# PADCFG_CTRL_PADCFG_CTRL_CFG0_04080000h register map
Vendor: Texas Instruments
Registers are 32-bit, access per field, reset 0x8214007 unless marked. A register's access mark holds for its fields unless they carry their own. Offsets are as the file gives them; [hi:lo] are bit positions; {n}, {i} and the like mark numbered series; 'fields as' and 'values as' point back to an identical list.

## PADCFG_CTRL_CFG0 (part 2 of 2)
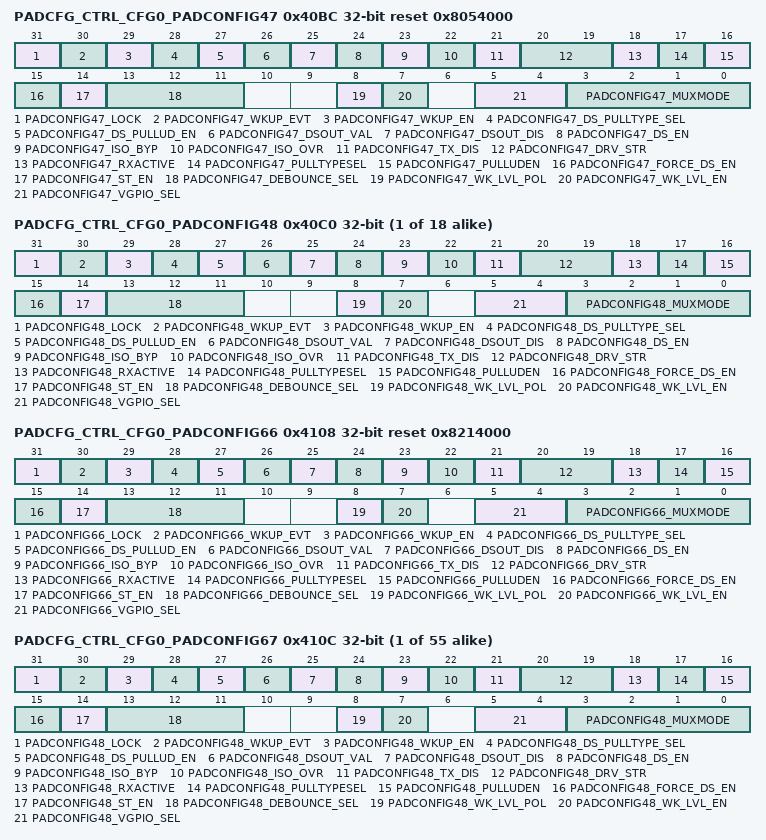
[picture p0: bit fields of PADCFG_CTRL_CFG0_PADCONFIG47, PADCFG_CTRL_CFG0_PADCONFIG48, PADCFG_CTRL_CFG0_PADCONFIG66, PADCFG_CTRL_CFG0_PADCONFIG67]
0x40BC PADCFG_CTRL_CFG0_PADCONFIG47 reset 0x8054000 — Register to control pin configuration and muxing
  [31] PADCONFIG47_LOCK rw — Lock 0 - Padconfig register is unlocked 1 - Padconfig register is locked from further writes Reset Source: mod_por_rst_n
  [30] PADCONFIG47_WKUP_EVT ro — Wakeup event status 0 - No wake event on pin 1 - Wake event occurred on pin Reset Source: mod_por_rst_n
  [29] PADCONFIG47_WKUP_EN rw — Wakeup enable 0 - Wakeup operation disabled 1 - Wakeup operation enabled Reset Source: mod_por_rst_n
  [28] PADCONFIG47_DS_PULLTYPE_SEL rw — Deep Sleep pull-up/down selection 0 - Offmode pulldown selected 1 - Offmode pullup selected Reset Source: mod_por_rst_n
  [27] PADCONFIG47_DS_PULLUD_EN rw — Deep Sleep pull-up/down enable (active low) 0 - Pullup / pulldown is enabled 1 - Pullup / pulldown is disabled Reset Source: mod_por_rst_n
  [26] PADCONFIG47_DSOUT_VAL rw — Deep Sleep output value 0 - Output value is 0 1 - Output value is 1 Reset Source: mod_por_rst_n
  [25] PADCONFIG47_DSOUT_DIS rw — Deep Sleep output disable 0 - Output enabled 1 - Output disabled Reset Source: mod_por_rst_n
  [24] PADCONFIG47_DS_EN rw — Deep Sleep override control 0 - IO keeps its previous state when Deep Sleep mode is active 1 - IO state is forced to OFF mode value when Deep Sleep mode is active Reset Source: mod_por_rst_n
  [23] PADCONFIG47_ISO_BYP rw — Isolation Bypass0 - IO isolation is preserved1 - IO isolation is bypassed Reset Source: mod_por_rst_n
  [22] PADCONFIG47_ISO_OVR rw — Isolation Override0 - IO isolation is preserved1 - IO isolation is overridden Reset Source: mod_por_rst_n
  [21] PADCONFIG47_TX_DIS rw — Driver Disable0 - Driver is enabled1 - Driver is disabled Reset Source: mod_por_rst_n
  [20:19] PADCONFIG47_DRV_STR rw — Drive Strength Control for dual volatge IOs. Selects the drive strength value for LVCMOS pins. For 1.8V only IO, bitundefined maps to Slew Control pin. Reset Source: mod_por_rst_n
  [18] PADCONFIG47_RXACTIVE rw — Input enable for the Pad0 - Receiver disabled1 - Receiver enabled Reset Source: mod_por_rst_n
  [17] PADCONFIG47_PULLTYPESEL rw — Pad Pullup / Pulldown type selection0 - Pulldown selected1 - Pullup selected Reset Source: mod_por_rst_n
  [16] PADCONFIG47_PULLUDEN rw — Pad Pullup / Pulldown enable. This is an active low signal.0 - Pullup / Pulldown enabled1 - Pullup / Pulldown disabled Reset Source: mod_por_rst_n
  [15] PADCONFIG47_FORCE_DS_EN rw — Enable pad Deep Sleep controls by overriding WKUP DM gating0 - Deep Sleep pad controls are gated by the WKUP DM1 - Activate Deep Sleep pad controls (override WKUP DM gating logic) Reset Source: mod_por_rst_n
  [14] PADCONFIG47_ST_EN rw — Receiver Schmitt Trigger enable 0 - Schmitt trigger input disabled 1 - Schmitt trigger input enabled Reset Source: mod_por_rst_n
  [13:11] PADCONFIG47_DEBOUNCE_SEL rw — Selects the debouce period for the pad. Reset Source: mod_por_rst_n
  [8] PADCONFIG47_WK_LVL_POL rw — Level Sensitive Wakeup PolarityThis bit is not relevant unless wk_lvl_en is set to 1'b1.0 - Low. A low (0) value on the pin causes a wakeup1 - High. A high (1) value on the pin causes a wakeup Reset Source: mod_por_rst_n
  [7] PADCONFIG47_WK_LVL_EN rw — Level Sensitive Wakeup Enable0 - Disabled. Wakeup is triggered by change of the pin input value1 - Enabled. Wakeup is triggered when the pin matches the value specified by wk_lvl_pol. The chosen polarity must be maintained. (e.g. until wakeup completion is confirmed) Reset Source: mod_por_rst_n
  [5:4] PADCONFIG47_VGPIO_SEL rw — Virtual MAIN_GPIO instance select.These bits select which instance of GPIO is used for this I/O pad. This allows protection between two different Processor virtual worlds. These bits have no effect if GPIO mode (muxmode=7) is not selected for the PAD. Refer Pinmux to identify if a pin supports virtual GPIO function or not.Field values (others are reserved):2'b00 - Implement GPIO in GPIO_0 instance2'b01 - Implement GPIO in GPIO_2 instance Reset Source: mod_por_rst_n
  [3:0] PADCONFIG47_MUXMODE rw — Pad functional signal mux selectionField values (others are reserved):4'b0000 - Mux Mode 04'b0001 - Mux Mode 14'b0010 - Mux Mode 24'b0011 - Mux Mode 34'b0100 - Mux Mode 44'b0101 - Mux Mode 54'b0110 - Mux Mode 64'b0111 - Mux Mode 74'b1000 - Mux Mode 84'b1001 - Mux Mode 94'b1010 - Mux Mode 104'b1011 - Mux Mode 114'b1100 - Mux Mode 124'b1101 - Mux Mode 134'b1110 - Mux Mode 144'b1111 - Mux Mode 15 Reset Source: mod_por_rst_n
{0x4000+4i} PADCFG_CTRL_CFG0_PADCONFIG{i} (i=48..65) — Register to control pin configuration and muxing
  [31] PADCONFIG{i}_LOCK rw — Lock 0 - Padconfig register is unlocked 1 - Padconfig register is locked from further writes Reset Source: mod_por_rst_n
  [30] PADCONFIG{i}_WKUP_EVT ro — Wakeup event status 0 - No wake event on pin 1 - Wake event occurred on pin Reset Source: mod_por_rst_n
  [29] PADCONFIG{i}_WKUP_EN rw — Wakeup enable 0 - Wakeup operation disabled 1 - Wakeup operation enabled Reset Source: mod_por_rst_n
  [28] PADCONFIG{i}_DS_PULLTYPE_SEL rw — Deep Sleep pull-up/down selection 0 - Offmode pulldown selected 1 - Offmode pullup selected Reset Source: mod_por_rst_n
  [27] PADCONFIG{i}_DS_PULLUD_EN rw — Deep Sleep pull-up/down enable (active low) 0 - Pullup / pulldown is enabled 1 - Pullup / pulldown is disabled Reset Source: mod_por_rst_n
  [26] PADCONFIG{i}_DSOUT_VAL rw — Deep Sleep output value 0 - Output value is 0 1 - Output value is 1 Reset Source: mod_por_rst_n
  [25] PADCONFIG{i}_DSOUT_DIS rw — Deep Sleep output disable 0 - Output enabled 1 - Output disabled Reset Source: mod_por_rst_n
  [24] PADCONFIG{i}_DS_EN rw — Deep Sleep override control 0 - IO keeps its previous state when Deep Sleep mode is active 1 - IO state is forced to OFF mode value when Deep Sleep mode is active Reset Source: mod_por_rst_n
  [23] PADCONFIG{i}_ISO_BYP rw — Isolation Bypass0 - IO isolation is preserved1 - IO isolation is bypassed Reset Source: mod_por_rst_n
  [22] PADCONFIG{i}_ISO_OVR rw — Isolation Override0 - IO isolation is preserved1 - IO isolation is overridden Reset Source: mod_por_rst_n
  [21] PADCONFIG{i}_TX_DIS rw — Driver Disable0 - Driver is enabled1 - Driver is disabled Reset Source: mod_por_rst_n
  [20:19] PADCONFIG{i}_DRV_STR rw — Drive Strength Control for dual volatge IOs. Selects the drive strength value for LVCMOS pins. For 1.8V only IO, bitundefined maps to Slew Control pin. Reset Source: mod_por_rst_n
  [18] PADCONFIG{i}_RXACTIVE rw — Input enable for the Pad0 - Receiver disabled1 - Receiver enabled Reset Source: mod_por_rst_n
  [17] PADCONFIG{i}_PULLTYPESEL rw — Pad Pullup / Pulldown type selection0 - Pulldown selected1 - Pullup selected Reset Source: mod_por_rst_n
  [16] PADCONFIG{i}_PULLUDEN rw — Pad Pullup / Pulldown enable. This is an active low signal.0 - Pullup / Pulldown enabled1 - Pullup / Pulldown disabled Reset Source: mod_por_rst_n
  [15] PADCONFIG{i}_FORCE_DS_EN rw — Enable pad Deep Sleep controls by overriding WKUP DM gating0 - Deep Sleep pad controls are gated by the WKUP DM1 - Activate Deep Sleep pad controls (override WKUP DM gating logic) Reset Source: mod_por_rst_n
  [14] PADCONFIG{i}_ST_EN rw — Receiver Schmitt Trigger enable 0 - Schmitt trigger input disabled 1 - Schmitt trigger input enabled Reset Source: mod_por_rst_n
  [13:11] PADCONFIG{i}_DEBOUNCE_SEL rw — Selects the debouce period for the pad. Reset Source: mod_por_rst_n
  [8] PADCONFIG{i}_WK_LVL_POL rw — Level Sensitive Wakeup PolarityThis bit is not relevant unless wk_lvl_en is set to 1'b1.0 - Low. A low (0) value on the pin causes a wakeup1 - High. A high (1) value on the pin causes a wakeup Reset Source: mod_por_rst_n
  [7] PADCONFIG{i}_WK_LVL_EN rw — Level Sensitive Wakeup Enable0 - Disabled. Wakeup is triggered by change of the pin input value1 - Enabled. Wakeup is triggered when the pin matches the value specified by wk_lvl_pol. The chosen polarity must be maintained. (e.g. until wakeup completion is confirmed) Reset Source: mod_por_rst_n
  [5:4] PADCONFIG{i}_VGPIO_SEL rw — Virtual MAIN_GPIO instance select.These bits select which instance of GPIO is used for this I/O pad. This allows protection between two different Processor virtual worlds. These bits have no effect if GPIO mode (muxmode=7) is not selected for the PAD. Refer Pinmux to identify if a pin supports virtual GPIO function or not.Field values (others are reserved):2'b00 - Implement GPIO in GPIO_0 instance2'b01 - Implement GPIO in GPIO_2 instance Reset Source: mod_por_rst_n
  [3:0] PADCONFIG{i}_MUXMODE rw — Pad functional signal mux selectionField values (others are reserved):4'b0000 - Mux Mode 04'b0001 - Mux Mode 14'b0010 - Mux Mode 24'b0011 - Mux Mode 34'b0100 - Mux Mode 44'b0101 - Mux Mode 54'b0110 - Mux Mode 64'b0111 - Mux Mode 74'b1000 - Mux Mode 84'b1001 - Mux Mode 94'b1010 - Mux Mode 104'b1011 - Mux Mode 114'b1100 - Mux Mode 124'b1101 - Mux Mode 134'b1110 - Mux Mode 144'b1111 - Mux Mode 15 Reset Source: mod_por_rst_n
0x4108 PADCFG_CTRL_CFG0_PADCONFIG66 reset 0x8214000 — Register to control pin configuration and muxing
  [31] PADCONFIG66_LOCK rw — Lock 0 - Padconfig register is unlocked 1 - Padconfig register is locked from further writes Reset Source: mod_por_rst_n
  [30] PADCONFIG66_WKUP_EVT ro — Wakeup event status 0 - No wake event on pin 1 - Wake event occurred on pin Reset Source: mod_por_rst_n
  [29] PADCONFIG66_WKUP_EN rw — Wakeup enable 0 - Wakeup operation disabled 1 - Wakeup operation enabled Reset Source: mod_por_rst_n
  [28] PADCONFIG66_DS_PULLTYPE_SEL rw — Deep Sleep pull-up/down selection 0 - Offmode pulldown selected 1 - Offmode pullup selected Reset Source: mod_por_rst_n
  [27] PADCONFIG66_DS_PULLUD_EN rw — Deep Sleep pull-up/down enable (active low) 0 - Pullup / pulldown is enabled 1 - Pullup / pulldown is disabled Reset Source: mod_por_rst_n
  [26] PADCONFIG66_DSOUT_VAL rw — Deep Sleep output value 0 - Output value is 0 1 - Output value is 1 Reset Source: mod_por_rst_n
  [25] PADCONFIG66_DSOUT_DIS rw — Deep Sleep output disable 0 - Output enabled 1 - Output disabled Reset Source: mod_por_rst_n
  [24] PADCONFIG66_DS_EN rw — Deep Sleep override control 0 - IO keeps its previous state when Deep Sleep mode is active 1 - IO state is forced to OFF mode value when Deep Sleep mode is active Reset Source: mod_por_rst_n
  [23] PADCONFIG66_ISO_BYP rw — Isolation Bypass0 - IO isolation is preserved1 - IO isolation is bypassed Reset Source: mod_por_rst_n
  [22] PADCONFIG66_ISO_OVR rw — Isolation Override0 - IO isolation is preserved1 - IO isolation is overridden Reset Source: mod_por_rst_n
  [21] PADCONFIG66_TX_DIS rw — Driver Disable0 - Driver is enabled1 - Driver is disabled Reset Source: mod_por_rst_n
  [20:19] PADCONFIG66_DRV_STR rw — Drive Strength Control for dual volatge IOs. Selects the drive strength value for LVCMOS pins. For 1.8V only IO, bitundefined maps to Slew Control pin. Reset Source: mod_por_rst_n
  [18] PADCONFIG66_RXACTIVE rw — Input enable for the Pad0 - Receiver disabled1 - Receiver enabled Reset Source: mod_por_rst_n
  [17] PADCONFIG66_PULLTYPESEL rw — Pad Pullup / Pulldown type selection0 - Pulldown selected1 - Pullup selected Reset Source: mod_por_rst_n
  [16] PADCONFIG66_PULLUDEN rw — Pad Pullup / Pulldown enable. This is an active low signal.0 - Pullup / Pulldown enabled1 - Pullup / Pulldown disabled Reset Source: mod_por_rst_n
  [15] PADCONFIG66_FORCE_DS_EN rw — Enable pad Deep Sleep controls by overriding WKUP DM gating0 - Deep Sleep pad controls are gated by the WKUP DM1 - Activate Deep Sleep pad controls (override WKUP DM gating logic) Reset Source: mod_por_rst_n
  [14] PADCONFIG66_ST_EN rw — Receiver Schmitt Trigger enable 0 - Schmitt trigger input disabled 1 - Schmitt trigger input enabled Reset Source: mod_por_rst_n
  [13:11] PADCONFIG66_DEBOUNCE_SEL rw — Selects the debouce period for the pad. Reset Source: mod_por_rst_n
  [8] PADCONFIG66_WK_LVL_POL rw — Level Sensitive Wakeup PolarityThis bit is not relevant unless wk_lvl_en is set to 1'b1.0 - Low. A low (0) value on the pin causes a wakeup1 - High. A high (1) value on the pin causes a wakeup Reset Source: mod_por_rst_n
  [7] PADCONFIG66_WK_LVL_EN rw — Level Sensitive Wakeup Enable0 - Disabled. Wakeup is triggered by change of the pin input value1 - Enabled. Wakeup is triggered when the pin matches the value specified by wk_lvl_pol. The chosen polarity must be maintained. (e.g. until wakeup completion is confirmed) Reset Source: mod_por_rst_n
  [5:4] PADCONFIG66_VGPIO_SEL rw — Virtual MAIN_GPIO instance select.These bits select which instance of GPIO is used for this I/O pad. This allows protection between two different Processor virtual worlds. These bits have no effect if GPIO mode (muxmode=7) is not selected for the PAD. Refer Pinmux to identify if a pin supports virtual GPIO function or not.Field values (others are reserved):2'b00 - Implement GPIO in GPIO_0 instance2'b01 - Implement GPIO in GPIO_2 instance Reset Source: mod_por_rst_n
  [3:0] PADCONFIG66_MUXMODE rw — Pad functional signal mux selectionField values (others are reserved):4'b0000 - Mux Mode 04'b0001 - Mux Mode 14'b0010 - Mux Mode 24'b0011 - Mux Mode 34'b0100 - Mux Mode 44'b0101 - Mux Mode 54'b0110 - Mux Mode 64'b0111 - Mux Mode 74'b1000 - Mux Mode 84'b1001 - Mux Mode 94'b1010 - Mux Mode 104'b1011 - Mux Mode 114'b1100 - Mux Mode 124'b1101 - Mux Mode 134'b1110 - Mux Mode 144'b1111 - Mux Mode 15 Reset Source: mod_por_rst_n
{0x4000+4i} PADCFG_CTRL_CFG0_PADCONFIG{i} (i=67..121) — Register to control pin configuration and muxing
  fields as PADCFG_CTRL_CFG0_PADCONFIG48
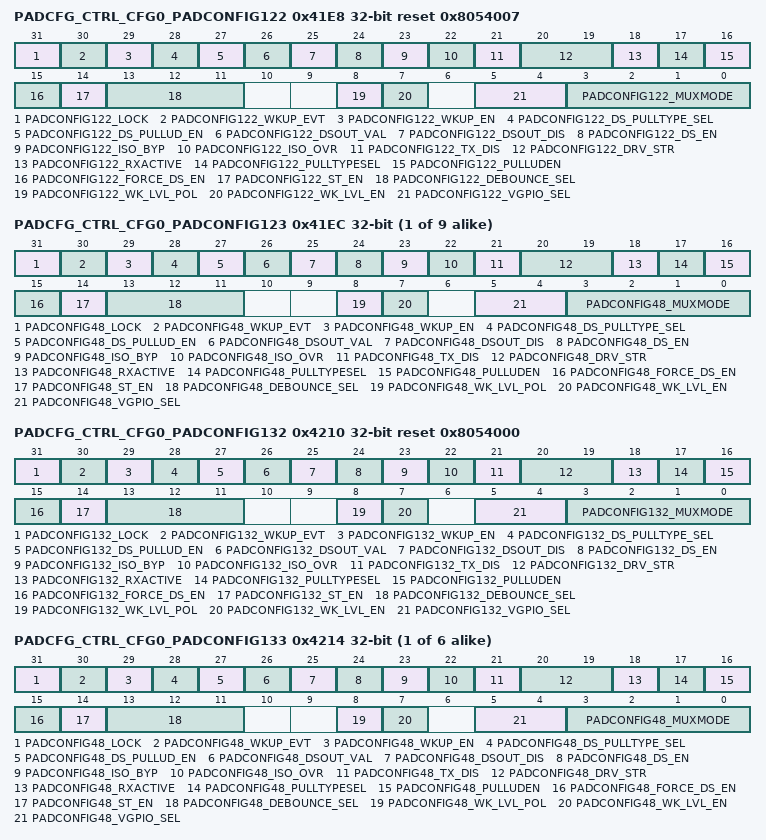
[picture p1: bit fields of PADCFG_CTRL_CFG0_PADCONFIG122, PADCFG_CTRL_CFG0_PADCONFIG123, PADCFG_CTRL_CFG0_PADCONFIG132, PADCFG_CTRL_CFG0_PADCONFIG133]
0x41E8 PADCFG_CTRL_CFG0_PADCONFIG122 reset 0x8054007 — Register to control pin configuration and muxing
  [31] PADCONFIG122_LOCK rw — Lock 0 - Padconfig register is unlocked 1 - Padconfig register is locked from further writes Reset Source: mod_por_rst_n
  [30] PADCONFIG122_WKUP_EVT ro — Wakeup event status 0 - No wake event on pin 1 - Wake event occurred on pin Reset Source: mod_por_rst_n
  [29] PADCONFIG122_WKUP_EN rw — Wakeup enable 0 - Wakeup operation disabled 1 - Wakeup operation enabled Reset Source: mod_por_rst_n
  [28] PADCONFIG122_DS_PULLTYPE_SEL rw — Deep Sleep pull-up/down selection 0 - Offmode pulldown selected 1 - Offmode pullup selected Reset Source: mod_por_rst_n
  [27] PADCONFIG122_DS_PULLUD_EN rw — Deep Sleep pull-up/down enable (active low) 0 - Pullup / pulldown is enabled 1 - Pullup / pulldown is disabled Reset Source: mod_por_rst_n
  [26] PADCONFIG122_DSOUT_VAL rw — Deep Sleep output value 0 - Output value is 0 1 - Output value is 1 Reset Source: mod_por_rst_n
  [25] PADCONFIG122_DSOUT_DIS rw — Deep Sleep output disable 0 - Output enabled 1 - Output disabled Reset Source: mod_por_rst_n
  [24] PADCONFIG122_DS_EN rw — Deep Sleep override control 0 - IO keeps its previous state when Deep Sleep mode is active 1 - IO state is forced to OFF mode value when Deep Sleep mode is active Reset Source: mod_por_rst_n
  [23] PADCONFIG122_ISO_BYP rw — Isolation Bypass0 - IO isolation is preserved1 - IO isolation is bypassed Reset Source: mod_por_rst_n
  [22] PADCONFIG122_ISO_OVR rw — Isolation Override0 - IO isolation is preserved1 - IO isolation is overridden Reset Source: mod_por_rst_n
  [21] PADCONFIG122_TX_DIS rw — Driver Disable0 - Driver is enabled1 - Driver is disabled Reset Source: mod_por_rst_n
  [20:19] PADCONFIG122_DRV_STR rw — Drive Strength Control for dual volatge IOs. Selects the drive strength value for LVCMOS pins. For 1.8V only IO, bitundefined maps to Slew Control pin. Reset Source: mod_por_rst_n
  [18] PADCONFIG122_RXACTIVE rw — Input enable for the Pad0 - Receiver disabled1 - Receiver enabled Reset Source: mod_por_rst_n
  [17] PADCONFIG122_PULLTYPESEL rw — Pad Pullup / Pulldown type selection0 - Pulldown selected1 - Pullup selected Reset Source: mod_por_rst_n
  [16] PADCONFIG122_PULLUDEN rw — Pad Pullup / Pulldown enable. This is an active low signal.0 - Pullup / Pulldown enabled1 - Pullup / Pulldown disabled Reset Source: mod_por_rst_n
  [15] PADCONFIG122_FORCE_DS_EN rw — Enable pad Deep Sleep controls by overriding WKUP DM gating0 - Deep Sleep pad controls are gated by the WKUP DM1 - Activate Deep Sleep pad controls (override WKUP DM gating logic) Reset Source: mod_por_rst_n
  [14] PADCONFIG122_ST_EN rw — Receiver Schmitt Trigger enable 0 - Schmitt trigger input disabled 1 - Schmitt trigger input enabled Reset Source: mod_por_rst_n
  [13:11] PADCONFIG122_DEBOUNCE_SEL rw — Selects the debouce period for the pad. Reset Source: mod_por_rst_n
  [8] PADCONFIG122_WK_LVL_POL rw — Level Sensitive Wakeup PolarityThis bit is not relevant unless wk_lvl_en is set to 1'b1.0 - Low. A low (0) value on the pin causes a wakeup1 - High. A high (1) value on the pin causes a wakeup Reset Source: mod_por_rst_n
  [7] PADCONFIG122_WK_LVL_EN rw — Level Sensitive Wakeup Enable0 - Disabled. Wakeup is triggered by change of the pin input value1 - Enabled. Wakeup is triggered when the pin matches the value specified by wk_lvl_pol. The chosen polarity must be maintained. (e.g. until wakeup completion is confirmed) Reset Source: mod_por_rst_n
  [5:4] PADCONFIG122_VGPIO_SEL rw — Virtual MAIN_GPIO instance select.These bits select which instance of GPIO is used for this I/O pad. This allows protection between two different Processor virtual worlds. These bits have no effect if GPIO mode (muxmode=7) is not selected for the PAD. Refer Pinmux to identify if a pin supports virtual GPIO function or not.Field values (others are reserved):2'b00 - Implement GPIO in GPIO_0 instance2'b01 - Implement GPIO in GPIO_2 instance Reset Source: mod_por_rst_n
  [3:0] PADCONFIG122_MUXMODE rw — Pad functional signal mux selectionField values (others are reserved):4'b0000 - Mux Mode 04'b0001 - Mux Mode 14'b0010 - Mux Mode 24'b0011 - Mux Mode 34'b0100 - Mux Mode 44'b0101 - Mux Mode 54'b0110 - Mux Mode 64'b0111 - Mux Mode 74'b1000 - Mux Mode 84'b1001 - Mux Mode 94'b1010 - Mux Mode 104'b1011 - Mux Mode 114'b1100 - Mux Mode 124'b1101 - Mux Mode 134'b1110 - Mux Mode 144'b1111 - Mux Mode 15 Reset Source: mod_por_rst_n
{0x4000+4i} PADCFG_CTRL_CFG0_PADCONFIG{i} (i=123..131) — Register to control pin configuration and muxing
  fields as PADCFG_CTRL_CFG0_PADCONFIG48
0x4210 PADCFG_CTRL_CFG0_PADCONFIG132 reset 0x8054000 — Register to control pin configuration and muxing
  [31] PADCONFIG132_LOCK rw — Lock 0 - Padconfig register is unlocked 1 - Padconfig register is locked from further writes Reset Source: mod_por_rst_n
  [30] PADCONFIG132_WKUP_EVT ro — Wakeup event status 0 - No wake event on pin 1 - Wake event occurred on pin Reset Source: mod_por_rst_n
  [29] PADCONFIG132_WKUP_EN rw — Wakeup enable 0 - Wakeup operation disabled 1 - Wakeup operation enabled Reset Source: mod_por_rst_n
  [28] PADCONFIG132_DS_PULLTYPE_SEL rw — Deep Sleep pull-up/down selection 0 - Offmode pulldown selected 1 - Offmode pullup selected Reset Source: mod_por_rst_n
  [27] PADCONFIG132_DS_PULLUD_EN rw — Deep Sleep pull-up/down enable (active low) 0 - Pullup / pulldown is enabled 1 - Pullup / pulldown is disabled Reset Source: mod_por_rst_n
  [26] PADCONFIG132_DSOUT_VAL rw — Deep Sleep output value 0 - Output value is 0 1 - Output value is 1 Reset Source: mod_por_rst_n
  [25] PADCONFIG132_DSOUT_DIS rw — Deep Sleep output disable 0 - Output enabled 1 - Output disabled Reset Source: mod_por_rst_n
  [24] PADCONFIG132_DS_EN rw — Deep Sleep override control 0 - IO keeps its previous state when Deep Sleep mode is active 1 - IO state is forced to OFF mode value when Deep Sleep mode is active Reset Source: mod_por_rst_n
  [23] PADCONFIG132_ISO_BYP rw — Isolation Bypass0 - IO isolation is preserved1 - IO isolation is bypassed Reset Source: mod_por_rst_n
  [22] PADCONFIG132_ISO_OVR rw — Isolation Override0 - IO isolation is preserved1 - IO isolation is overridden Reset Source: mod_por_rst_n
  [21] PADCONFIG132_TX_DIS rw — Driver Disable0 - Driver is enabled1 - Driver is disabled Reset Source: mod_por_rst_n
  [20:19] PADCONFIG132_DRV_STR rw — Drive Strength Control for dual volatge IOs. Selects the drive strength value for LVCMOS pins. For 1.8V only IO, bitundefined maps to Slew Control pin. Reset Source: mod_por_rst_n
  [18] PADCONFIG132_RXACTIVE rw — Input enable for the Pad0 - Receiver disabled1 - Receiver enabled Reset Source: mod_por_rst_n
  [17] PADCONFIG132_PULLTYPESEL rw — Pad Pullup / Pulldown type selection0 - Pulldown selected1 - Pullup selected Reset Source: mod_por_rst_n
  [16] PADCONFIG132_PULLUDEN rw — Pad Pullup / Pulldown enable. This is an active low signal.0 - Pullup / Pulldown enabled1 - Pullup / Pulldown disabled Reset Source: mod_por_rst_n
  [15] PADCONFIG132_FORCE_DS_EN rw — Enable pad Deep Sleep controls by overriding WKUP DM gating0 - Deep Sleep pad controls are gated by the WKUP DM1 - Activate Deep Sleep pad controls (override WKUP DM gating logic) Reset Source: mod_por_rst_n
  [14] PADCONFIG132_ST_EN rw — Receiver Schmitt Trigger enable 0 - Schmitt trigger input disabled 1 - Schmitt trigger input enabled Reset Source: mod_por_rst_n
  [13:11] PADCONFIG132_DEBOUNCE_SEL rw — Selects the debouce period for the pad. Reset Source: mod_por_rst_n
  [8] PADCONFIG132_WK_LVL_POL rw — Level Sensitive Wakeup PolarityThis bit is not relevant unless wk_lvl_en is set to 1'b1.0 - Low. A low (0) value on the pin causes a wakeup1 - High. A high (1) value on the pin causes a wakeup Reset Source: mod_por_rst_n
  [7] PADCONFIG132_WK_LVL_EN rw — Level Sensitive Wakeup Enable0 - Disabled. Wakeup is triggered by change of the pin input value1 - Enabled. Wakeup is triggered when the pin matches the value specified by wk_lvl_pol. The chosen polarity must be maintained. (e.g. until wakeup completion is confirmed) Reset Source: mod_por_rst_n
  [5:4] PADCONFIG132_VGPIO_SEL rw — Virtual MAIN_GPIO instance select.These bits select which instance of GPIO is used for this I/O pad. This allows protection between two different Processor virtual worlds. These bits have no effect if GPIO mode (muxmode=7) is not selected for the PAD. Refer Pinmux to identify if a pin supports virtual GPIO function or not.Field values (others are reserved):2'b00 - Implement GPIO in GPIO_0 instance2'b01 - Implement GPIO in GPIO_2 instance Reset Source: mod_por_rst_n
  [3:0] PADCONFIG132_MUXMODE rw — Pad functional signal mux selectionField values (others are reserved):4'b0000 - Mux Mode 04'b0001 - Mux Mode 14'b0010 - Mux Mode 24'b0011 - Mux Mode 34'b0100 - Mux Mode 44'b0101 - Mux Mode 54'b0110 - Mux Mode 64'b0111 - Mux Mode 74'b1000 - Mux Mode 84'b1001 - Mux Mode 94'b1010 - Mux Mode 104'b1011 - Mux Mode 114'b1100 - Mux Mode 124'b1101 - Mux Mode 134'b1110 - Mux Mode 144'b1111 - Mux Mode 15 Reset Source: mod_por_rst_n
{0x4000+4i} PADCFG_CTRL_CFG0_PADCONFIG{i} (i=133..138) — Register to control pin configuration and muxing
  fields as PADCFG_CTRL_CFG0_PADCONFIG48
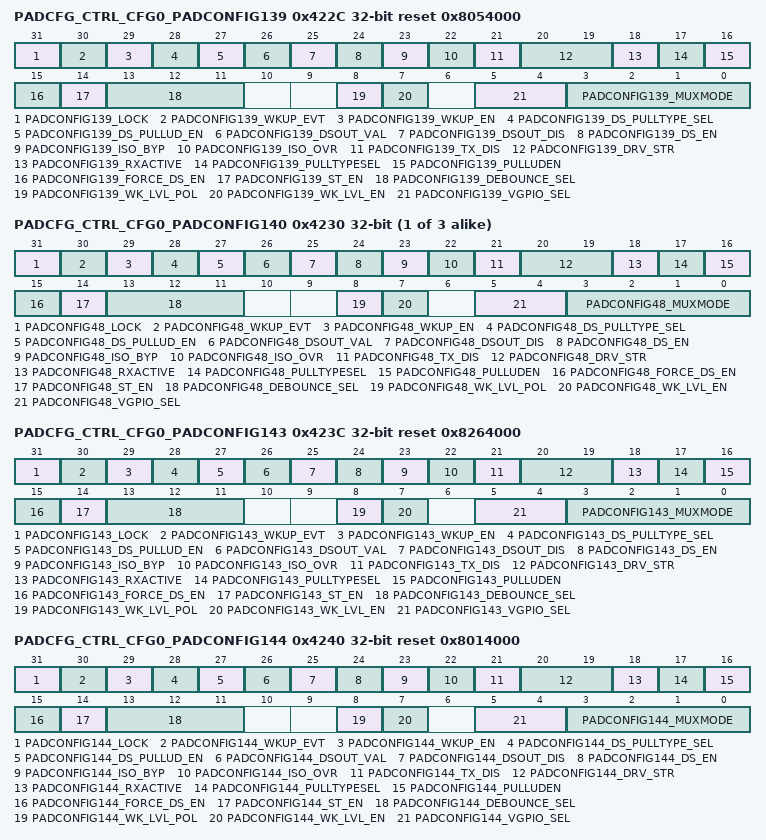
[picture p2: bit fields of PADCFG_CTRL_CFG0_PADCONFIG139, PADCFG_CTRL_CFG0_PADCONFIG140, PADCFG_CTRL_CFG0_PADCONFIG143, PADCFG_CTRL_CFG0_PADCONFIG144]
0x422C PADCFG_CTRL_CFG0_PADCONFIG139 reset 0x8054000 — Register to control pin configuration and muxing
  [31] PADCONFIG139_LOCK rw — Lock 0 - Padconfig register is unlocked 1 - Padconfig register is locked from further writes Reset Source: mod_por_rst_n
  [30] PADCONFIG139_WKUP_EVT ro — Wakeup event status 0 - No wake event on pin 1 - Wake event occurred on pin Reset Source: mod_por_rst_n
  [29] PADCONFIG139_WKUP_EN rw — Wakeup enable 0 - Wakeup operation disabled 1 - Wakeup operation enabled Reset Source: mod_por_rst_n
  [28] PADCONFIG139_DS_PULLTYPE_SEL rw — Deep Sleep pull-up/down selection 0 - Offmode pulldown selected 1 - Offmode pullup selected Reset Source: mod_por_rst_n
  [27] PADCONFIG139_DS_PULLUD_EN rw — Deep Sleep pull-up/down enable (active low) 0 - Pullup / pulldown is enabled 1 - Pullup / pulldown is disabled Reset Source: mod_por_rst_n
  [26] PADCONFIG139_DSOUT_VAL rw — Deep Sleep output value 0 - Output value is 0 1 - Output value is 1 Reset Source: mod_por_rst_n
  [25] PADCONFIG139_DSOUT_DIS rw — Deep Sleep output disable 0 - Output enabled 1 - Output disabled Reset Source: mod_por_rst_n
  [24] PADCONFIG139_DS_EN rw — Deep Sleep override control 0 - IO keeps its previous state when Deep Sleep mode is active 1 - IO state is forced to OFF mode value when Deep Sleep mode is active Reset Source: mod_por_rst_n
  [23] PADCONFIG139_ISO_BYP rw — Isolation Bypass0 - IO isolation is preserved1 - IO isolation is bypassed Reset Source: mod_por_rst_n
  [22] PADCONFIG139_ISO_OVR rw — Isolation Override0 - IO isolation is preserved1 - IO isolation is overridden Reset Source: mod_por_rst_n
  [21] PADCONFIG139_TX_DIS rw — Driver Disable0 - Driver is enabled1 - Driver is disabled Reset Source: mod_por_rst_n
  [20:19] PADCONFIG139_DRV_STR rw — Drive Strength Control for dual volatge IOs. Selects the drive strength value for LVCMOS pins. For 1.8V only IO, bitundefined maps to Slew Control pin. Reset Source: mod_por_rst_n
  [18] PADCONFIG139_RXACTIVE rw — Input enable for the Pad0 - Receiver disabled1 - Receiver enabled Reset Source: mod_por_rst_n
  [17] PADCONFIG139_PULLTYPESEL rw — Pad Pullup / Pulldown type selection0 - Pulldown selected1 - Pullup selected Reset Source: mod_por_rst_n
  [16] PADCONFIG139_PULLUDEN rw — Pad Pullup / Pulldown enable. This is an active low signal.0 - Pullup / Pulldown enabled1 - Pullup / Pulldown disabled Reset Source: mod_por_rst_n
  [15] PADCONFIG139_FORCE_DS_EN rw — Enable pad Deep Sleep controls by overriding WKUP DM gating0 - Deep Sleep pad controls are gated by the WKUP DM1 - Activate Deep Sleep pad controls (override WKUP DM gating logic) Reset Source: mod_por_rst_n
  [14] PADCONFIG139_ST_EN rw — Receiver Schmitt Trigger enable 0 - Schmitt trigger input disabled 1 - Schmitt trigger input enabled Reset Source: mod_por_rst_n
  [13:11] PADCONFIG139_DEBOUNCE_SEL rw — Selects the debouce period for the pad. Reset Source: mod_por_rst_n
  [8] PADCONFIG139_WK_LVL_POL rw — Level Sensitive Wakeup PolarityThis bit is not relevant unless wk_lvl_en is set to 1'b1.0 - Low. A low (0) value on the pin causes a wakeup1 - High. A high (1) value on the pin causes a wakeup Reset Source: mod_por_rst_n
  [7] PADCONFIG139_WK_LVL_EN rw — Level Sensitive Wakeup Enable0 - Disabled. Wakeup is triggered by change of the pin input value1 - Enabled. Wakeup is triggered when the pin matches the value specified by wk_lvl_pol. The chosen polarity must be maintained. (e.g. until wakeup completion is confirmed) Reset Source: mod_por_rst_n
  [5:4] PADCONFIG139_VGPIO_SEL rw — Virtual MAIN_GPIO instance select.These bits select which instance of GPIO is used for this I/O pad. This allows protection between two different Processor virtual worlds. These bits have no effect if GPIO mode (muxmode=7) is not selected for the PAD. Refer Pinmux to identify if a pin supports virtual GPIO function or not.Field values (others are reserved):2'b00 - Implement GPIO in GPIO_0 instance2'b01 - Implement GPIO in GPIO_2 instance Reset Source: mod_por_rst_n
  [3:0] PADCONFIG139_MUXMODE rw — Pad functional signal mux selectionField values (others are reserved):4'b0000 - Mux Mode 04'b0001 - Mux Mode 14'b0010 - Mux Mode 24'b0011 - Mux Mode 34'b0100 - Mux Mode 44'b0101 - Mux Mode 54'b0110 - Mux Mode 64'b0111 - Mux Mode 74'b1000 - Mux Mode 84'b1001 - Mux Mode 94'b1010 - Mux Mode 104'b1011 - Mux Mode 114'b1100 - Mux Mode 124'b1101 - Mux Mode 134'b1110 - Mux Mode 144'b1111 - Mux Mode 15 Reset Source: mod_por_rst_n
{0x4000+4i} PADCFG_CTRL_CFG0_PADCONFIG{i} (i=140..142) — Register to control pin configuration and muxing
  fields as PADCFG_CTRL_CFG0_PADCONFIG48
0x423C PADCFG_CTRL_CFG0_PADCONFIG143 reset 0x8264000 — Register to control pin configuration and muxing
  [31] PADCONFIG143_LOCK rw — Lock 0 - Padconfig register is unlocked 1 - Padconfig register is locked from further writes Reset Source: mod_por_rst_n
  [30] PADCONFIG143_WKUP_EVT ro — Wakeup event status 0 - No wake event on pin 1 - Wake event occurred on pin Reset Source: mod_por_rst_n
  [29] PADCONFIG143_WKUP_EN rw — Wakeup enable 0 - Wakeup operation disabled 1 - Wakeup operation enabled Reset Source: mod_por_rst_n
  [28] PADCONFIG143_DS_PULLTYPE_SEL rw — Deep Sleep pull-up/down selection 0 - Offmode pulldown selected 1 - Offmode pullup selected Reset Source: mod_por_rst_n
  [27] PADCONFIG143_DS_PULLUD_EN rw — Deep Sleep pull-up/down enable (active low) 0 - Pullup / pulldown is enabled 1 - Pullup / pulldown is disabled Reset Source: mod_por_rst_n
  [26] PADCONFIG143_DSOUT_VAL rw — Deep Sleep output value 0 - Output value is 0 1 - Output value is 1 Reset Source: mod_por_rst_n
  [25] PADCONFIG143_DSOUT_DIS rw — Deep Sleep output disable 0 - Output enabled 1 - Output disabled Reset Source: mod_por_rst_n
  [24] PADCONFIG143_DS_EN rw — Deep Sleep override control 0 - IO keeps its previous state when Deep Sleep mode is active 1 - IO state is forced to OFF mode value when Deep Sleep mode is active Reset Source: mod_por_rst_n
  [23] PADCONFIG143_ISO_BYP rw — Isolation Bypass0 - IO isolation is preserved1 - IO isolation is bypassed Reset Source: mod_por_rst_n
  [22] PADCONFIG143_ISO_OVR rw — Isolation Override0 - IO isolation is preserved1 - IO isolation is overridden Reset Source: mod_por_rst_n
  [21] PADCONFIG143_TX_DIS rw — Driver Disable0 - Driver is enabled1 - Driver is disabled Reset Source: mod_por_rst_n
  [20:19] PADCONFIG143_DRV_STR rw — Drive Strength Control for dual volatge IOs. Selects the drive strength value for LVCMOS pins. For 1.8V only IO, bitundefined maps to Slew Control pin. Reset Source: mod_por_rst_n
  [18] PADCONFIG143_RXACTIVE rw — Input enable for the Pad0 - Receiver disabled1 - Receiver enabled Reset Source: mod_por_rst_n
  [17] PADCONFIG143_PULLTYPESEL rw — Pad Pullup / Pulldown type selection0 - Pulldown selected1 - Pullup selected Reset Source: mod_por_rst_n
  [16] PADCONFIG143_PULLUDEN rw — Pad Pullup / Pulldown enable. This is an active low signal.0 - Pullup / Pulldown enabled1 - Pullup / Pulldown disabled Reset Source: mod_por_rst_n
  [15] PADCONFIG143_FORCE_DS_EN rw — Enable pad Deep Sleep controls by overriding WKUP DM gating0 - Deep Sleep pad controls are gated by the WKUP DM1 - Activate Deep Sleep pad controls (override WKUP DM gating logic) Reset Source: mod_por_rst_n
  [14] PADCONFIG143_ST_EN rw — Receiver Schmitt Trigger enable 0 - Schmitt trigger input disabled 1 - Schmitt trigger input enabled Reset Source: mod_por_rst_n
  [13:11] PADCONFIG143_DEBOUNCE_SEL rw — Selects the debouce period for the pad. Reset Source: mod_por_rst_n
  [8] PADCONFIG143_WK_LVL_POL rw — Level Sensitive Wakeup PolarityThis bit is not relevant unless wk_lvl_en is set to 1'b1.0 - Low. A low (0) value on the pin causes a wakeup1 - High. A high (1) value on the pin causes a wakeup Reset Source: mod_por_rst_n
  [7] PADCONFIG143_WK_LVL_EN rw — Level Sensitive Wakeup Enable0 - Disabled. Wakeup is triggered by change of the pin input value1 - Enabled. Wakeup is triggered when the pin matches the value specified by wk_lvl_pol. The chosen polarity must be maintained. (e.g. until wakeup completion is confirmed) Reset Source: mod_por_rst_n
  [5:4] PADCONFIG143_VGPIO_SEL rw — Virtual MAIN_GPIO instance select.These bits select which instance of GPIO is used for this I/O pad. This allows protection between two different Processor virtual worlds. These bits have no effect if GPIO mode (muxmode=7) is not selected for the PAD. Refer Pinmux to identify if a pin supports virtual GPIO function or not.Field values (others are reserved):2'b00 - Implement GPIO in GPIO_0 instance2'b01 - Implement GPIO in GPIO_2 instance Reset Source: mod_por_rst_n
  [3:0] PADCONFIG143_MUXMODE rw — Pad functional signal mux selectionField values (others are reserved):4'b0000 - Mux Mode 04'b0001 - Mux Mode 14'b0010 - Mux Mode 24'b0011 - Mux Mode 34'b0100 - Mux Mode 44'b0101 - Mux Mode 54'b0110 - Mux Mode 64'b0111 - Mux Mode 74'b1000 - Mux Mode 84'b1001 - Mux Mode 94'b1010 - Mux Mode 104'b1011 - Mux Mode 114'b1100 - Mux Mode 124'b1101 - Mux Mode 134'b1110 - Mux Mode 144'b1111 - Mux Mode 15 Reset Source: mod_por_rst_n
0x4240 PADCFG_CTRL_CFG0_PADCONFIG144 reset 0x8014000 — Register to control pin configuration and muxing
  [31] PADCONFIG144_LOCK rw — Lock 0 - Padconfig register is unlocked 1 - Padconfig register is locked from further writes Reset Source: mod_por_rst_n
  [30] PADCONFIG144_WKUP_EVT ro — Wakeup event status 0 - No wake event on pin 1 - Wake event occurred on pin Reset Source: mod_por_rst_n
  [29] PADCONFIG144_WKUP_EN rw — Wakeup enable 0 - Wakeup operation disabled 1 - Wakeup operation enabled Reset Source: mod_por_rst_n
  [28] PADCONFIG144_DS_PULLTYPE_SEL rw — Deep Sleep pull-up/down selection 0 - Offmode pulldown selected 1 - Offmode pullup selected Reset Source: mod_por_rst_n
  [27] PADCONFIG144_DS_PULLUD_EN rw — Deep Sleep pull-up/down enable (active low) 0 - Pullup / pulldown is enabled 1 - Pullup / pulldown is disabled Reset Source: mod_por_rst_n
  [26] PADCONFIG144_DSOUT_VAL rw — Deep Sleep output value 0 - Output value is 0 1 - Output value is 1 Reset Source: mod_por_rst_n
  [25] PADCONFIG144_DSOUT_DIS rw — Deep Sleep output disable 0 - Output enabled 1 - Output disabled Reset Source: mod_por_rst_n
  [24] PADCONFIG144_DS_EN rw — Deep Sleep override control 0 - IO keeps its previous state when Deep Sleep mode is active 1 - IO state is forced to OFF mode value when Deep Sleep mode is active Reset Source: mod_por_rst_n
  [23] PADCONFIG144_ISO_BYP rw — Isolation Bypass0 - IO isolation is preserved1 - IO isolation is bypassed Reset Source: mod_por_rst_n
  [22] PADCONFIG144_ISO_OVR rw — Isolation Override0 - IO isolation is preserved1 - IO isolation is overridden Reset Source: mod_por_rst_n
  [21] PADCONFIG144_TX_DIS rw — Driver Disable0 - Driver is enabled1 - Driver is disabled Reset Source: mod_por_rst_n
  [20:19] PADCONFIG144_DRV_STR rw — Drive Strength Control for dual volatge IOs. Selects the drive strength value for LVCMOS pins. For 1.8V only IO, bitundefined maps to Slew Control pin. Reset Source: mod_por_rst_n
  [18] PADCONFIG144_RXACTIVE rw — Input enable for the Pad0 - Receiver disabled1 - Receiver enabled Reset Source: mod_por_rst_n
  [17] PADCONFIG144_PULLTYPESEL rw — Pad Pullup / Pulldown type selection0 - Pulldown selected1 - Pullup selected Reset Source: mod_por_rst_n
  [16] PADCONFIG144_PULLUDEN rw — Pad Pullup / Pulldown enable. This is an active low signal.0 - Pullup / Pulldown enabled1 - Pullup / Pulldown disabled Reset Source: mod_por_rst_n
  [15] PADCONFIG144_FORCE_DS_EN rw — Enable pad Deep Sleep controls by overriding WKUP DM gating0 - Deep Sleep pad controls are gated by the WKUP DM1 - Activate Deep Sleep pad controls (override WKUP DM gating logic) Reset Source: mod_por_rst_n
  [14] PADCONFIG144_ST_EN rw — Receiver Schmitt Trigger enable 0 - Schmitt trigger input disabled 1 - Schmitt trigger input enabled Reset Source: mod_por_rst_n
  [13:11] PADCONFIG144_DEBOUNCE_SEL rw — Selects the debouce period for the pad. Reset Source: mod_por_rst_n
  [8] PADCONFIG144_WK_LVL_POL rw — Level Sensitive Wakeup PolarityThis bit is not relevant unless wk_lvl_en is set to 1'b1.0 - Low. A low (0) value on the pin causes a wakeup1 - High. A high (1) value on the pin causes a wakeup Reset Source: mod_por_rst_n
  [7] PADCONFIG144_WK_LVL_EN rw — Level Sensitive Wakeup Enable0 - Disabled. Wakeup is triggered by change of the pin input value1 - Enabled. Wakeup is triggered when the pin matches the value specified by wk_lvl_pol. The chosen polarity must be maintained. (e.g. until wakeup completion is confirmed) Reset Source: mod_por_rst_n
  [5:4] PADCONFIG144_VGPIO_SEL rw — Virtual MAIN_GPIO instance select.These bits select which instance of GPIO is used for this I/O pad. This allows protection between two different Processor virtual worlds. These bits have no effect if GPIO mode (muxmode=7) is not selected for the PAD. Refer Pinmux to identify if a pin supports virtual GPIO function or not.Field values (others are reserved):2'b00 - Implement GPIO in GPIO_0 instance2'b01 - Implement GPIO in GPIO_2 instance Reset Source: mod_por_rst_n
  [3:0] PADCONFIG144_MUXMODE rw — Pad functional signal mux selectionField values (others are reserved):4'b0000 - Mux Mode 04'b0001 - Mux Mode 14'b0010 - Mux Mode 24'b0011 - Mux Mode 34'b0100 - Mux Mode 44'b0101 - Mux Mode 54'b0110 - Mux Mode 64'b0111 - Mux Mode 74'b1000 - Mux Mode 84'b1001 - Mux Mode 94'b1010 - Mux Mode 104'b1011 - Mux Mode 114'b1100 - Mux Mode 124'b1101 - Mux Mode 134'b1110 - Mux Mode 144'b1111 - Mux Mode 15 Reset Source: mod_por_rst_n
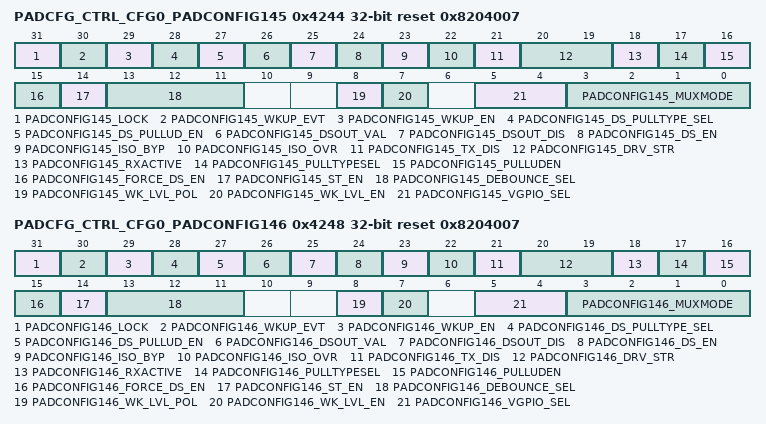
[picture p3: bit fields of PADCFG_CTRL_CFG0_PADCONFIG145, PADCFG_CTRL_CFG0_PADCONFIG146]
0x4244 PADCFG_CTRL_CFG0_PADCONFIG145 reset 0x8204007 — Register to control pin configuration and muxing
  [31] PADCONFIG145_LOCK rw — Lock 0 - Padconfig register is unlocked 1 - Padconfig register is locked from further writes Reset Source: mod_por_rst_n
  [30] PADCONFIG145_WKUP_EVT ro — Wakeup event status 0 - No wake event on pin 1 - Wake event occurred on pin Reset Source: mod_por_rst_n
  [29] PADCONFIG145_WKUP_EN rw — Wakeup enable 0 - Wakeup operation disabled 1 - Wakeup operation enabled Reset Source: mod_por_rst_n
  [28] PADCONFIG145_DS_PULLTYPE_SEL rw — Deep Sleep pull-up/down selection 0 - Offmode pulldown selected 1 - Offmode pullup selected Reset Source: mod_por_rst_n
  [27] PADCONFIG145_DS_PULLUD_EN rw — Deep Sleep pull-up/down enable (active low) 0 - Pullup / pulldown is enabled 1 - Pullup / pulldown is disabled Reset Source: mod_por_rst_n
  [26] PADCONFIG145_DSOUT_VAL rw — Deep Sleep output value 0 - Output value is 0 1 - Output value is 1 Reset Source: mod_por_rst_n
  [25] PADCONFIG145_DSOUT_DIS rw — Deep Sleep output disable 0 - Output enabled 1 - Output disabled Reset Source: mod_por_rst_n
  [24] PADCONFIG145_DS_EN rw — Deep Sleep override control 0 - IO keeps its previous state when Deep Sleep mode is active 1 - IO state is forced to OFF mode value when Deep Sleep mode is active Reset Source: mod_por_rst_n
  [23] PADCONFIG145_ISO_BYP rw — Isolation Bypass0 - IO isolation is preserved1 - IO isolation is bypassed Reset Source: mod_por_rst_n
  [22] PADCONFIG145_ISO_OVR rw — Isolation Override0 - IO isolation is preserved1 - IO isolation is overridden Reset Source: mod_por_rst_n
  [21] PADCONFIG145_TX_DIS rw — Driver Disable0 - Driver is enabled1 - Driver is disabled Reset Source: mod_por_rst_n
  [20:19] PADCONFIG145_DRV_STR rw — Drive Strength Control for dual volatge IOs. Selects the drive strength value for LVCMOS pins. For 1.8V only IO, bitundefined maps to Slew Control pin. Reset Source: mod_por_rst_n
  [18] PADCONFIG145_RXACTIVE rw — Input enable for the Pad0 - Receiver disabled1 - Receiver enabled Reset Source: mod_por_rst_n
  [17] PADCONFIG145_PULLTYPESEL rw — Pad Pullup / Pulldown type selection0 - Pulldown selected1 - Pullup selected Reset Source: mod_por_rst_n
  [16] PADCONFIG145_PULLUDEN rw — Pad Pullup / Pulldown enable. This is an active low signal.0 - Pullup / Pulldown enabled1 - Pullup / Pulldown disabled Reset Source: mod_por_rst_n
  [15] PADCONFIG145_FORCE_DS_EN rw — Enable pad Deep Sleep controls by overriding WKUP DM gating0 - Deep Sleep pad controls are gated by the WKUP DM1 - Activate Deep Sleep pad controls (override WKUP DM gating logic) Reset Source: mod_por_rst_n
  [14] PADCONFIG145_ST_EN rw — Receiver Schmitt Trigger enable 0 - Schmitt trigger input disabled 1 - Schmitt trigger input enabled Reset Source: mod_por_rst_n
  [13:11] PADCONFIG145_DEBOUNCE_SEL rw — Selects the debouce period for the pad. Reset Source: mod_por_rst_n
  [8] PADCONFIG145_WK_LVL_POL rw — Level Sensitive Wakeup PolarityThis bit is not relevant unless wk_lvl_en is set to 1'b1.0 - Low. A low (0) value on the pin causes a wakeup1 - High. A high (1) value on the pin causes a wakeup Reset Source: mod_por_rst_n
  [7] PADCONFIG145_WK_LVL_EN rw — Level Sensitive Wakeup Enable0 - Disabled. Wakeup is triggered by change of the pin input value1 - Enabled. Wakeup is triggered when the pin matches the value specified by wk_lvl_pol. The chosen polarity must be maintained. (e.g. until wakeup completion is confirmed) Reset Source: mod_por_rst_n
  [5:4] PADCONFIG145_VGPIO_SEL rw — Virtual MAIN_GPIO instance select.These bits select which instance of GPIO is used for this I/O pad. This allows protection between two different Processor virtual worlds. These bits have no effect if GPIO mode (muxmode=7) is not selected for the PAD. Refer Pinmux to identify if a pin supports virtual GPIO function or not.Field values (others are reserved):2'b00 - Implement GPIO in GPIO_0 instance2'b01 - Implement GPIO in GPIO_2 instance Reset Source: mod_por_rst_n
  [3:0] PADCONFIG145_MUXMODE rw — Pad functional signal mux selectionField values (others are reserved):4'b0000 - Mux Mode 04'b0001 - Mux Mode 14'b0010 - Mux Mode 24'b0011 - Mux Mode 34'b0100 - Mux Mode 44'b0101 - Mux Mode 54'b0110 - Mux Mode 64'b0111 - Mux Mode 74'b1000 - Mux Mode 84'b1001 - Mux Mode 94'b1010 - Mux Mode 104'b1011 - Mux Mode 114'b1100 - Mux Mode 124'b1101 - Mux Mode 134'b1110 - Mux Mode 144'b1111 - Mux Mode 15 Reset Source: mod_por_rst_n
0x4248 PADCFG_CTRL_CFG0_PADCONFIG146 reset 0x8204007 — Register to control pin configuration and muxing
  [31] PADCONFIG146_LOCK rw — Lock 0 - Padconfig register is unlocked 1 - Padconfig register is locked from further writes Reset Source: mod_por_rst_n
  [30] PADCONFIG146_WKUP_EVT ro — Wakeup event status 0 - No wake event on pin 1 - Wake event occurred on pin Reset Source: mod_por_rst_n
  [29] PADCONFIG146_WKUP_EN rw — Wakeup enable 0 - Wakeup operation disabled 1 - Wakeup operation enabled Reset Source: mod_por_rst_n
  [28] PADCONFIG146_DS_PULLTYPE_SEL rw — Deep Sleep pull-up/down selection 0 - Offmode pulldown selected 1 - Offmode pullup selected Reset Source: mod_por_rst_n
  [27] PADCONFIG146_DS_PULLUD_EN rw — Deep Sleep pull-up/down enable (active low) 0 - Pullup / pulldown is enabled 1 - Pullup / pulldown is disabled Reset Source: mod_por_rst_n
  [26] PADCONFIG146_DSOUT_VAL rw — Deep Sleep output value 0 - Output value is 0 1 - Output value is 1 Reset Source: mod_por_rst_n
  [25] PADCONFIG146_DSOUT_DIS rw — Deep Sleep output disable 0 - Output enabled 1 - Output disabled Reset Source: mod_por_rst_n
  [24] PADCONFIG146_DS_EN rw — Deep Sleep override control 0 - IO keeps its previous state when Deep Sleep mode is active 1 - IO state is forced to OFF mode value when Deep Sleep mode is active Reset Source: mod_por_rst_n
  [23] PADCONFIG146_ISO_BYP rw — Isolation Bypass0 - IO isolation is preserved1 - IO isolation is bypassed Reset Source: mod_por_rst_n
  [22] PADCONFIG146_ISO_OVR rw — Isolation Override0 - IO isolation is preserved1 - IO isolation is overridden Reset Source: mod_por_rst_n
  [21] PADCONFIG146_TX_DIS rw — Driver Disable0 - Driver is enabled1 - Driver is disabled Reset Source: mod_por_rst_n
  [20:19] PADCONFIG146_DRV_STR rw — Drive Strength Control for dual volatge IOs. Selects the drive strength value for LVCMOS pins. For 1.8V only IO, bitundefined maps to Slew Control pin. Reset Source: mod_por_rst_n
  [18] PADCONFIG146_RXACTIVE rw — Input enable for the Pad0 - Receiver disabled1 - Receiver enabled Reset Source: mod_por_rst_n
  [17] PADCONFIG146_PULLTYPESEL rw — Pad Pullup / Pulldown type selection0 - Pulldown selected1 - Pullup selected Reset Source: mod_por_rst_n
  [16] PADCONFIG146_PULLUDEN rw — Pad Pullup / Pulldown enable. This is an active low signal.0 - Pullup / Pulldown enabled1 - Pullup / Pulldown disabled Reset Source: mod_por_rst_n
  [15] PADCONFIG146_FORCE_DS_EN rw — Enable pad Deep Sleep controls by overriding WKUP DM gating0 - Deep Sleep pad controls are gated by the WKUP DM1 - Activate Deep Sleep pad controls (override WKUP DM gating logic) Reset Source: mod_por_rst_n
  [14] PADCONFIG146_ST_EN rw — Receiver Schmitt Trigger enable 0 - Schmitt trigger input disabled 1 - Schmitt trigger input enabled Reset Source: mod_por_rst_n
  [13:11] PADCONFIG146_DEBOUNCE_SEL rw — Selects the debouce period for the pad. Reset Source: mod_por_rst_n
  [8] PADCONFIG146_WK_LVL_POL rw — Level Sensitive Wakeup PolarityThis bit is not relevant unless wk_lvl_en is set to 1'b1.0 - Low. A low (0) value on the pin causes a wakeup1 - High. A high (1) value on the pin causes a wakeup Reset Source: mod_por_rst_n
  [7] PADCONFIG146_WK_LVL_EN rw — Level Sensitive Wakeup Enable0 - Disabled. Wakeup is triggered by change of the pin input value1 - Enabled. Wakeup is triggered when the pin matches the value specified by wk_lvl_pol. The chosen polarity must be maintained. (e.g. until wakeup completion is confirmed) Reset Source: mod_por_rst_n
  [5:4] PADCONFIG146_VGPIO_SEL rw — Virtual MAIN_GPIO instance select.These bits select which instance of GPIO is used for this I/O pad. This allows protection between two different Processor virtual worlds. These bits have no effect if GPIO mode (muxmode=7) is not selected for the PAD. Refer Pinmux to identify if a pin supports virtual GPIO function or not.Field values (others are reserved):2'b00 - Implement GPIO in GPIO_0 instance2'b01 - Implement GPIO in GPIO_2 instance Reset Source: mod_por_rst_n
  [3:0] PADCONFIG146_MUXMODE rw — Pad functional signal mux selectionField values (others are reserved):4'b0000 - Mux Mode 04'b0001 - Mux Mode 14'b0010 - Mux Mode 24'b0011 - Mux Mode 34'b0100 - Mux Mode 44'b0101 - Mux Mode 54'b0110 - Mux Mode 64'b0111 - Mux Mode 74'b1000 - Mux Mode 84'b1001 - Mux Mode 94'b1010 - Mux Mode 104'b1011 - Mux Mode 114'b1100 - Mux Mode 124'b1101 - Mux Mode 134'b1110 - Mux Mode 144'b1111 - Mux Mode 15 Reset Source: mod_por_rst_n
